# STM32G563 register map
File version: 2.0.0
CPU: CM33 r0p4, little endian, MPU, FPU, 4 interrupt priority bits
Registers are 32-bit, read-write, reset 0x0 unless marked. A register's access mark holds for its fields unless they carry their own. Offsets are from the block's base; [hi:lo] are bit positions; {n}, {i} and the like mark numbered series.

## ADCC12 — ADCC address block description
Base 0x42020300
Same registers: ADCC3 0x42020700, ADCC12_S 0x52020300, ADCC3_S 0x52020700
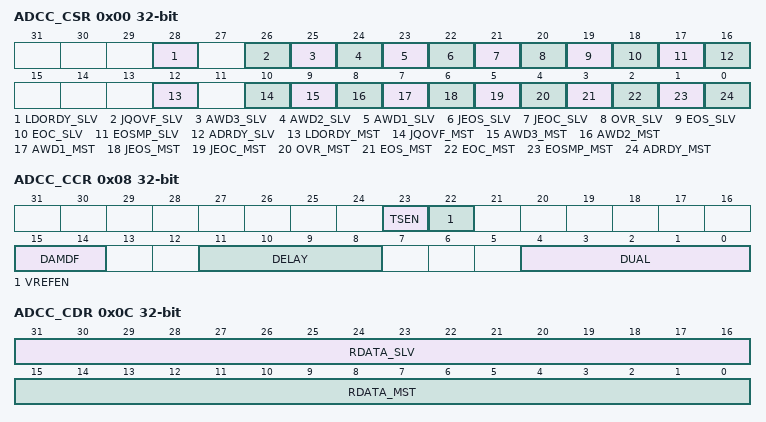
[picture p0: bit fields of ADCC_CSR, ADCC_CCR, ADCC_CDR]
0x00 ADCC_CSR ro — ADC common status register
  [28] LDORDY_SLV — ADC internal voltage regulator flag of the slave ADC
  [26] JQOVF_SLV — Injected context queue overflow flag of the slave ADC
  [25] AWD3_SLV — Analog watchdog 3 flag of the slave ADC
  [24] AWD2_SLV — Analog watchdog 2 flag of the slave ADC
  [23] AWD1_SLV — Analog watchdog 1 flag of the slave ADC
  [22] JEOS_SLV — End of injected sequence flag of the slave ADC
  [21] JEOC_SLV — End of injected conversion flag of the slave ADC
  [20] OVR_SLV — Overrun flag of the slave ADC
  [19] EOS_SLV — End of regular sequence flag of the slave ADC. This bit is a copy of the EOS bit in the corresponding ADC_ISR register.
  [18] EOC_SLV — End of regular conversion of the slave ADC
  [17] EOSMP_SLV — End of sampling phase flag of the slave ADC
  [16] ADRDY_SLV — Slave ADC ready
  [12] LDORDY_MST — ADC internal voltage regulator flag of the master ADC
  [10] JQOVF_MST — Injected context queue overflow flag of the master ADC
  [9] AWD3_MST — Analog watchdog 3 flag of the master ADC
  [8] AWD2_MST — Analog watchdog 2 flag of the master ADC
  [7] AWD1_MST — Analog watchdog 1 flag of the master ADC
  [6] JEOS_MST — End of injected sequence flag of the master ADC
  [5] JEOC_MST — End of injected conversion flag of the master ADC
  [4] OVR_MST — Overrun flag of the master ADC
  [3] EOS_MST — End of regular sequence flag of the master ADC
  [2] EOC_MST — End of regular conversion of the master ADC
  [1] EOSMP_MST — End of Sampling phase flag of the master ADC
  [0] ADRDY_MST — Master ADC ready
0x08 ADCC_CCR — ADC common control register
  [23] TSEN — Temperature sensor voltage enable
    0=Temperature sensor channel disabled; 1=Temperature sensor channel enabled
  [22] VREFEN — VREFINT enable
    0=VREFINT channel disabled; 1=VREFINT channel enabled
  [15:14] DAMDF — Dual ADC mode data format
    0=Dual ADC mode without data packing (ADCC_CDR and ADCC_CDR2 registers not used); 2=Data formatting mode for any data width (ADCC_CDR data register is used when the data width is less than 16 bits, otherwise ADCC_CDR2 register is used); 3=Data formatting mode for data width lower that 8 bits (ADCC_CDR data register is used)
  [11:8] DELAY — Delay between two sampling phases
  [4:0] DUAL — Dual ADC mode selection
    0=Independent mode; 1=Combined regular simultaneous + Injected simultaneous mode; 2=Combined regular simultaneous + Alternate trigger mode; 3=Combined interleaved mode + Injected simultaneous mode; 5=Injected simultaneous mode only; 6=Regular simultaneous mode only; 7=Interleaved mode only; 9=Alternate trigger mode only
0x0C ADCC_CDR ro — ADC common regular data register for dual mode
  [31:16] RDATA_SLV — Regular data of the slave ADC
  [15:0] RDATA_MST — Regular data of the master ADC.
0x10 ADCC_CDR2 ro — ADC common regular data register for dual mode
  [31:0] RDATA_ALT — Regular data of the master/slave alternated ADCs.

## AES — AES register block
Base 0x46006000
Same registers: AES_S 0x56006000
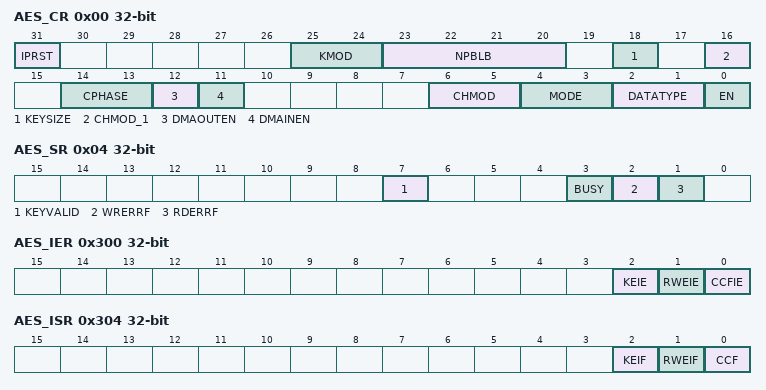
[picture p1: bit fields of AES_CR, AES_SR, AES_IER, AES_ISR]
0x00 AES_CR — AES control register
  [31] IPRST — AES peripheral software reset
  [25:24] KMOD — Key mode selection
    0=Normal key mode. Key registers are freely usable.; 2=Shared key mode. If shared key mode is properly initialized in SAES peripheral, the AES peripheral automatically loads its key registers with the data stored in the SAES key registers. The key value is available in AES key registers when BUSY bit is cleared and KEYVALID is set in the AES_SR register. Key error flag KEIF is set otherwise in the AES_ISR register.
  [23:20] NPBLB — Number of padding bytes in last block
    0=All bytes are valid (no padding); 1=Padding for the last LSB byte; 15=Padding for the 15 LSB bytes of last block
  [18] KEYSIZE — Key size selection
    0=128-bit; 1=256-bit
  [16] CHMOD_1 — CHMOD[2]
  [14:13] CPHASE — Chaining phase selection
    0=Initialization phase; 1=Header phase; 2=Payload phase; 3=Final phase
  [12] DMAOUTEN — DMA output enable
    0=Disable; 1=Enable
  [11] DMAINEN — DMA input enable
    0=Disable; 1=Enable
  [6:5] CHMOD — CHMOD[1:0]: Chaining mode
    0=Electronic codebook (ECB); 1=Cipher-block chaining (CBC); 2=Counter mode (CTR); 3=Galois counter mode (GCM) and Galois message authentication code (GMAC)
  [4:3] MODE — Operating mode
    0=Encryption; 1=Key derivation (or key preparation), for ECB/CBC decryption only; 2=Decryption
  [2:1] DATATYPE
    0=No swapping (32-bit data); 1=Half-word swapping (16-bit data); 2=Byte swapping (8-bit data); 3=Bit-level swapping
  [0] EN — Enable
    0=Disable; 1=Enable
0x04 AES_SR ro — AES status register
  [7] KEYVALID — Key valid flag
    0=Key not valid; 1=Key valid
  [3] BUSY
    0=Idle; 1=Busy
  [2] WRERRF — Write error flag
    0=No error; 1=Unexpected write to AES_DINR register occurred during computation or data output phase
  [1] RDERRF — Read error flag
    0=No error; 1=Unexpected read to AES_DOUTR register occurred during computation or data input phase
0x08 AES_DINR wo — AES data input register
  [31:0] DIN — Data input
0x0C AES_DOUTR ro — AES data output register
  [31:0] DOUT — Data output
{0x10+4i} AES_KEYR{i} wo (i=0..3) — AES key register {i}
  [31:0] KEY — Cryptographic key, bits [{32i+31}:{32i}]
{0x20+4i} AES_IVR{i} (i=0..3) — AES initialization vector register {i}
  [31:0] IVI — Initialization vector input, bits [{32i+31}:{32i}]
{0x20+4i} AES_KEYR{i} wo (i=4..7) — AES key register {i}
  [31:0] KEY — Cryptographic key, bits [{32i+31}:{32i}]
{0x40+4i} AES_SUSPR{i} (i=0..7) — AES suspend registers
  [31:0] SUSP — Suspend data
0x300 AES_IER — AES interrupt enable register
  [all] fields
    0=Disabled (masked); 1=Enabled (not masked)
  [2] KEIE — Key error interrupt enable
  [1] RWEIE — Read or write error interrupt enable
  [0] CCFIE — Computation complete flag interrupt enable
0x304 AES_ISR ro — AES interrupt status register
  [2] KEIF — Key error interrupt flag
    0=No key error detected; 1=Key information failed to load into key registers
  [1] RWEIF — Read or write error interrupt flag
    0=No read or write error detected; 1=Read or write error detected
  [0] CCF — Computation complete flag
    0=Not completed; 1=Completed
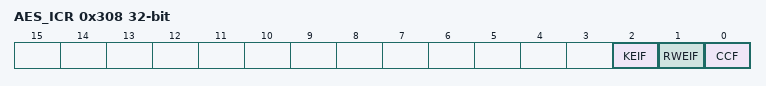
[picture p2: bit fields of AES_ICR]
0x308 AES_ICR wo — AES interrupt clear register
  [2] KEIF — Key error interrupt flag clear
  [1] RWEIF — Read or write error interrupt flag clear
  [0] CCF — Computation complete flag clear

## Notices in the file
Copyright (c) 2026 STMicroelectronics.
SPDX-License-Identifier: Apache-2.0
Licensed under the Apache License, Version 2.0 (the "License");
you may not use this file except in compliance with the License.
You may obtain a copy of the License at
http://www.apache.org/licenses/LICENSE-2.0
Unless required by applicable law or agreed to in writing, software
distributed under the License is distributed on an "AS IS" BASIS,
WITHOUT WARRANTIES OR CONDITIONS OF ANY KIND, either express or implied.
See the License for the specific language governing permissions and
limitations under the License.
